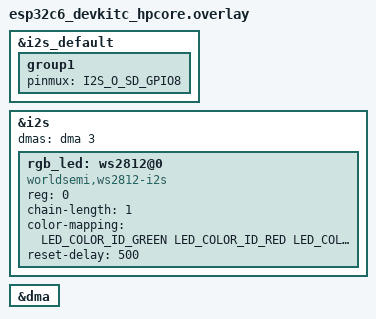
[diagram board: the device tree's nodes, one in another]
#include <zephyr/dt-bindings/led/led.h>

&i2s_default {
	group1 {
		pinmux = <I2S_O_SD_GPIO8>;
	};
};

i2s_led: &i2s {
	status = "okay";

	dmas = <&dma 3>;
	dma-names = "tx";

	rgb_led: ws2812@0 {
		compatible = "worldsemi,ws2812-i2s";

		reg = <0>;
		chain-length = <1>;
		color-mapping = <LED_COLOR_ID_GREEN
		        		 LED_COLOR_ID_RED
				         LED_COLOR_ID_BLUE>;
		reset-delay = <500>;
	};
};

&dma {
	status = "okay";
};
